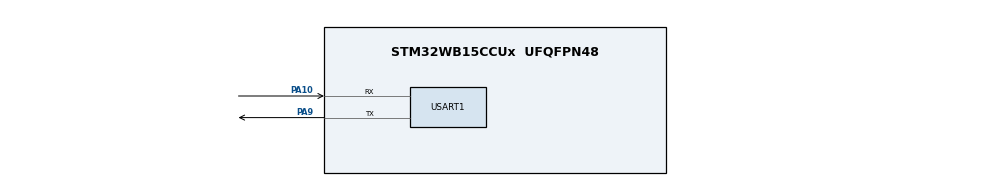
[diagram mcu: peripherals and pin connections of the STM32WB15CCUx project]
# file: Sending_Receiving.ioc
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Mcu.Family=STM32WB
Mcu.Name=STM32WB15CCUx
Mcu.Package=UFQFPN48
NUCLEO-WB15CC.BUTTON=1
NUCLEO-WB15CC.BUTTON2=1
NUCLEO-WB15CC.BUTTON3=1
NUCLEO-WB15CC.LD1=true
NUCLEO-WB15CC.LD2=true
NUCLEO-WB15CC.LD3=true
NUCLEO-WB15CC.VCP=false
NVIC.EXTI0_IRQn=true\:0\:0\:false\:false\:true\:true\:true\:true
NVIC.EXTI4_IRQn=true\:0\:0\:false\:false\:true\:true\:true\:true
NVIC.EXTI9_5_IRQn=true\:0\:0\:false\:false\:true\:true\:true\:true
NVIC.HSEM_IRQn=true\:0\:0\:false\:false\:true\:false\:true\:true
NVIC.IPCC_C1_RX_IRQn=true\:0\:0\:false\:false\:true\:true\:true\:true
NVIC.IPCC_C1_TX_IRQn=true\:0\:0\:false\:false\:true\:true\:true\:true
NVIC.PriorityGroup=NVIC_PRIORITYGROUP_4
NVIC.RTC_WKUP_IRQn=true\:0\:0\:false\:false\:true\:true\:true\:true
NVIC.TIM1_BRK_IRQn=true\:0\:0\:false\:false\:true\:true\:true\:true
NVIC.TIM1_CC_IRQn=true\:0\:0\:false\:false\:true\:true\:true\:true
NVIC.TIM1_TRG_COM_IRQn=true\:0\:0\:false\:false\:true\:true\:true\:true
NVIC.TIM1_UP_IRQn=true\:0\:0\:false\:false\:true\:true\:true\:true
OSC_IN.GPIO_Label=RCC_OSC_IN
OSC_IN.Mode=HSE-External-Oscillator
OSC_IN.Signal=RCC_OSC_IN
OSC_OUT.GPIO_Label=RCC_OSC_OUT
OSC_OUT.Mode=HSE-External-Oscillator
OSC_OUT.Signal=RCC_OSC_OUT
PA10.Mode=Asynchronous
PA10.Signal=USART1_RX
PA13.GPIO_Label=JTMS
PA13.Signal=SYS_JTMS-SWDIO
PA14.GPIO_Label=JTCK
PA14.Signal=SYS_JTCK-SWCLK
PA9.Mode=Asynchronous
PA9.Signal=USART1_TX
PB3.GPIO_Label=JTDO
PB3.Signal=SYS_JTDO-SWO
PC14-OSC32_IN.GPIO_Label=RCC_OSC32_IN
PC14-OSC32_IN.Mode=LSE-External-Oscillator
PC14-OSC32_IN.Signal=RCC_OSC32_IN
PC15-OSC32_OUT.GPIO_Label=RCC_OSC32_OUT
PC15-OSC32_OUT.Mode=LSE-External-Oscillator
PC15-OSC32_OUT.Signal=RCC_OSC32_OUT
ProjectManager.HeapSize=0x200
ProjectManager.StackSize=0x400
ProjectManager.TargetToolchain=STM32CubeIDE
RCC.AHBFreq_Value=32000000
RCC.APB1Freq_Value=32000000
RCC.APB1TimFreq_Value=32000000
RCC.APB2Freq_Value=32000000
RCC.APB2TimFreq_Value=32000000
RCC.APB3Freq_Value=16000000
RCC.CortexFreq_Value=32000000
RCC.HCLKFreq_Value=32000000
RCC.HSE_VALUE=32000000
RCC.HSI_VALUE=16000000
RCC.LSE_Drive_Capability=RCC_LSEDRIVE_LOW
RCC.MSIClockRange=RCC_MSIRANGE_10
RCC.RFWKPClockSelection=RCC_RFWKPCLKSOURCE_LSE
RCC.RTCClockSelection=RCC_RTCCLKSOURCE_LSE
RCC.SYSCLKFreq_VALUE=32000000
RCC.VCOOutputFreq_Value=256000000
RF1.Mode=RF1_Activate
RF1.Signal=RF_RF1
STM32_WPAN.AD_TYPE_COMPLETE_LOCAL_NAME=STM32-NUCLEO
STM32_WPAN.AD_TYPE_COMPLETE_LOCAL_NAME_LENGTH=13
STM32_WPAN.CFG_LSCLK_LSE=0
STM32_WPAN.CUSTOM_P2P_SERVER=Disabled
STM32_WPAN.CUSTOM_TEMPLATE=Enabled
STM32_WPAN.INCLUDE_AD_TYPE_COMPLETE_LOCAL_NAME=1
STM32_WPAN.NUMBER_OF_SERVICES=1
STM32_WPAN.SERVICE1_CHAR1_GATT_NOTIFY_ATTRIBUTE_WRITE=GATT_NOTIFY_ATTRIBUTE_WRITE
STM32_WPAN.SERVICE1_CHAR1_GATT_NOTIFY_READ_REQ_AND_WAIT_FOR_APPL_RESP=\ 
STM32_WPAN.SERVICE1_CHAR1_GATT_NOTIFY_WRITE_REQ_AND_WAIT_FOR_APPL_RESP=\ 
STM32_WPAN.SERVICE1_CHAR1_LONG_NAME=myCharWrite
STM32_WPAN.SERVICE1_CHAR1_PROP_WRITE=CHAR_PROP_WRITE
STM32_WPAN.SERVICE1_CHAR1_SHORT_NAME=myCharWrite
STM32_WPAN.SERVICE1_CHAR1_VALUE_LENGTH=7
STM32_WPAN.SERVICE1_CHAR2_GATT_NOTIFY_ATTRIBUTE_WRITE=GATT_NOTIFY_ATTRIBUTE_WRITE
STM32_WPAN.SERVICE1_CHAR2_GATT_NOTIFY_NOTIFICATION_COMPLETION=GATT_NOTIFY_NOTIFICATION_COMPLETION
STM32_WPAN.SERVICE1_CHAR2_GATT_NOTIFY_READ_REQ_AND_WAIT_FOR_APPL_RESP=GATT_NOTIFY_READ_REQ_AND_WAIT_FOR_APPL_RESP
STM32_WPAN.SERVICE1_CHAR2_GATT_NOTIFY_WRITE_REQ_AND_WAIT_FOR_APPL_RESP=GATT_NOTIFY_WRITE_REQ_AND_WAIT_FOR_APPL_RESP
STM32_WPAN.SERVICE1_CHAR2_LONG_NAME=myCharNotify
STM32_WPAN.SERVICE1_CHAR2_PROP_NOTIFY=CHAR_PROP_NOTIFY
STM32_WPAN.SERVICE1_CHAR2_SHORT_NAME=myCharNotify
STM32_WPAN.SERVICE1_CHAR2_UUID=10 00
STM32_WPAN.SERVICE1_CHAR2_VALUE_LENGTH=7
STM32_WPAN.SERVICE1_LONG_NAME=mySvc
STM32_WPAN.SERVICE1_NUMBER_OF_CHARACTERISTICS=2
STM32_WPAN.SERVICE1_SHORT_NAME=mySvc
STM32_WPAN.SERVICE1_UUID_128_INPUT_TYPE=0
TIM1.Period=49999
TIM1.Prescaler=63
USART1.VirtualMode-Asynchronous=VM_ASYNC
VP_HSEM_VS_HSEM.Mode=HSEM_Activate
VP_IPCC_VS_IPCC.Mode=IPCC_Activate
VP_MEMORYMAP_VS_MEMORYMAP.Mode=CurAppReg
VP_NUCLEO-WB15CC_VS_BSP_COMMON.Mode=COMMON
VP_RTC_VS_RTC_Activate.Mode=RTC_Enabled
VP_RTC_VS_RTC_WakeUp_intern.Mode=WakeUp
VP_SEQUENCER_VS_SEQUENCER.Mode=SEQUENCER_Enabled
VP_STM32_WPAN_VS_BLE_HOST.Mode=STM32_WPAN_Enabled
VP_TIM1_VS_ClockSourceINT.Mode=Internal
VP_TINY_LPM_VS_TINY_LPM.Mode=TINY_LPM_Enabled
board=NUCLEO-WB15CC

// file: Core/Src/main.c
/* USER CODE BEGIN Header */
/**
  ******************************************************************************
  * @file           : main.c
  * @brief          : Main program body
  ******************************************************************************
  * @attention
  *
  * Copyright (c) 2025 STMicroelectronics.
  * All rights reserved.
  *
  * This software is licensed under terms that can be found in the LICENSE file
  * in the root directory of this software component.
  * If no LICENSE file comes with this software, it is provided AS-IS.
  *
  ******************************************************************************
  */
/* USER CODE END Header */
#include "main.h"

/* USER CODE BEGIN PD */
#include "custom_app.h"
/* USER CODE END PD */

IPCC_HandleTypeDef hipcc;

RTC_HandleTypeDef hrtc;

TIM_HandleTypeDef htim1;

UART_HandleTypeDef huart1;

/* USER CODE BEGIN PV */
led_struct_t LED[] = {
    {LED1_GPIO_PORT, LED1_PIN},
    {LED2_GPIO_PORT, LED2_PIN},
    {LED3_GPIO_PORT, LED3_PIN}
};
/* USER CODE END PV */

void SystemClock_Config(void);
void PeriphCommonClock_Config(void);
static void MX_RF_Init(void);
static void MX_GPIO_Init(void);
static void MX_IPCC_Init(void);
static void MX_RTC_Init(void);
static void MX_USART1_UART_Init(void);
static void MX_TIM1_Init(void);

/* USER CODE BEGIN 0 */
int __io_putchar(int ch) //function used to print() in usart
{
  if (ch == '\n') {
    __io_putchar('\r');
  }

  HAL_UART_Transmit(&huart1, (uint8_t*)&ch, 1, HAL_MAX_DELAY);

  return 1;
}
/* USER CODE END 0 */

int main(void)
{

  /* MCU Configuration--------------------------------------------------------*/

  /* Reset of all peripherals, Initializes the Flash interface and the Systick. */
  HAL_Init();
  /* Config code for STM32_WPAN (HSE Tuning must be done before system clock configuration) */
  MX_APPE_Config();

  /* Configure the system clock */
  SystemClock_Config();

  /* Configure the peripherals common clocks */
  PeriphCommonClock_Config();

  /* IPCC initialisation */
  MX_IPCC_Init();

  /* Initialize all configured peripherals */
  MX_RF_Init();
  MX_GPIO_Init();
  MX_RTC_Init();
  MX_USART1_UART_Init();
  MX_TIM1_Init();

  /* Init code for STM32_WPAN */
  MX_APPE_Init();

  /* Initialize leds */
  BSP_LED_Init(LED_BLUE);
  BSP_LED_Init(LED_GREEN);
  BSP_LED_Init(LED_RED);

  /* Initialize USER push-button, will be used to trigger an interrupt each time it's pressed.*/
  BSP_PB_Init(BUTTON_SW1, BUTTON_MODE_EXTI);
  BSP_PB_Init(BUTTON_SW2, BUTTON_MODE_EXTI);
  BSP_PB_Init(BUTTON_SW3, BUTTON_MODE_EXTI);

  /* Infinite loop */
  /* USER CODE BEGIN WHILE */
  uint32_t last_time = 0;  // Przechowuje czas ostatniego wysłania danych
  printf("Starting");
//  HAL_TIM_Base_Start_IT(&htim1);
  while (1)
  {

    /* USER CODE END WHILE */
    MX_APPE_Process();

  }
}

void SystemClock_Config(void)
{
  RCC_OscInitTypeDef RCC_OscInitStruct = {0};
  RCC_ClkInitTypeDef RCC_ClkInitStruct = {0};

  /** Configure LSE Drive Capability
  */
  HAL_PWR_EnableBkUpAccess();
  __HAL_RCC_LSEDRIVE_CONFIG(RCC_LSEDRIVE_LOW);

  /** Initializes the RCC Oscillators according to the specified parameters
  * in the RCC_OscInitTypeDef structure.
  */
  RCC_OscInitStruct.OscillatorType = RCC_OSCILLATORTYPE_HSI|RCC_OSCILLATORTYPE_HSE
                              |RCC_OSCILLATORTYPE_LSE|RCC_OSCILLATORTYPE_MSI;
  RCC_OscInitStruct.HSEState = RCC_HSE_ON;
  RCC_OscInitStruct.LSEState = RCC_LSE_ON;
  RCC_OscInitStruct.HSIState = RCC_HSI_ON;
  RCC_OscInitStruct.MSIState = RCC_MSI_ON;
  RCC_OscInitStruct.HSICalibrationValue = RCC_HSICALIBRATION_DEFAULT;
  RCC_OscInitStruct.MSICalibrationValue = RCC_MSICALIBRATION_DEFAULT;
  RCC_OscInitStruct.MSIClockRange = RCC_MSIRANGE_10;
  RCC_OscInitStruct.PLL.PLLState = RCC_PLL_NONE;
  if (HAL_RCC_OscConfig(&RCC_OscInitStruct) != HAL_OK)
  {
    Error_Handler();
  }

  /** Configure the SYSCLKSource, HCLK, PCLK1 and PCLK2 clocks dividers
  */
  RCC_ClkInitStruct.ClockType = RCC_CLOCKTYPE_HCLK4|RCC_CLOCKTYPE_HCLK2
                              |RCC_CLOCKTYPE_HCLK|RCC_CLOCKTYPE_SYSCLK
                              |RCC_CLOCKTYPE_PCLK1|RCC_CLOCKTYPE_PCLK2;
  RCC_ClkInitStruct.SYSCLKSource = RCC_SYSCLKSOURCE_MSI;
  RCC_ClkInitStruct.AHBCLKDivider = RCC_SYSCLK_DIV1;
  RCC_ClkInitStruct.APB1CLKDivider = RCC_HCLK_DIV1;
  RCC_ClkInitStruct.APB2CLKDivider = RCC_HCLK_DIV1;
  RCC_ClkInitStruct.AHBCLK2Divider = RCC_SYSCLK_DIV1;
  RCC_ClkInitStruct.AHBCLK4Divider = RCC_SYSCLK_DIV1;

  if (HAL_RCC_ClockConfig(&RCC_ClkInitStruct, FLASH_LATENCY_1) != HAL_OK)
  {
    Error_Handler();
  }

  /** Enable MSI Auto calibration
  */
  HAL_RCCEx_EnableMSIPLLMode();
}

void PeriphCommonClock_Config(void)
{
  RCC_PeriphCLKInitTypeDef PeriphClkInitStruct = {0};

  /** Initializes the peripherals clock
  */
  PeriphClkInitStruct.PeriphClockSelection = RCC_PERIPHCLK_SMPS|RCC_PERIPHCLK_RFWAKEUP;
  PeriphClkInitStruct.RFWakeUpClockSelection = RCC_RFWKPCLKSOURCE_LSE;
  PeriphClkInitStruct.SmpsClockSelection = RCC_SMPSCLKSOURCE_HSI;
  PeriphClkInitStruct.SmpsDivSelection = RCC_SMPSCLKDIV_RANGE1;

  if (HAL_RCCEx_PeriphCLKConfig(&PeriphClkInitStruct) != HAL_OK)
  {
    Error_Handler();
  }
}

static void MX_IPCC_Init(void)
{

  hipcc.Instance = IPCC;
  if (HAL_IPCC_Init(&hipcc) != HAL_OK)
  {
    Error_Handler();
  }

}

static void MX_RF_Init(void)
{

}

static void MX_RTC_Init(void)
{

  /** Initialize RTC Only
  */
  hrtc.Instance = RTC;
  hrtc.Init.HourFormat = RTC_HOURFORMAT_24;
  hrtc.Init.AsynchPrediv = CFG_RTC_ASYNCH_PRESCALER;
  hrtc.Init.SynchPrediv = CFG_RTC_SYNCH_PRESCALER;
  hrtc.Init.OutPut = RTC_OUTPUT_DISABLE;
  hrtc.Init.OutPutPolarity = RTC_OUTPUT_POLARITY_HIGH;
  hrtc.Init.OutPutRemap = RTC_OUTPUT_REMAP_NONE;
  if (HAL_RTC_Init(&hrtc) != HAL_OK)
  {
    Error_Handler();
  }

  /** Enable the WakeUp
  */
  if (HAL_RTCEx_SetWakeUpTimer_IT(&hrtc, 0, RTC_WAKEUPCLOCK_RTCCLK_DIV16) != HAL_OK)
  {
    Error_Handler();
  }

}

static void MX_TIM1_Init(void)
{

  TIM_ClockConfigTypeDef sClockSourceConfig = {0};
  TIM_MasterConfigTypeDef sMasterConfig = {0};

  htim1.Instance = TIM1;
  htim1.Init.Prescaler = 63;
  htim1.Init.CounterMode = TIM_COUNTERMODE_UP;
  htim1.Init.Period = 49999;
  htim1.Init.ClockDivision = TIM_CLOCKDIVISION_DIV1;
  htim1.Init.RepetitionCounter = 0;
  htim1.Init.AutoReloadPreload = TIM_AUTORELOAD_PRELOAD_DISABLE;
  if (HAL_TIM_Base_Init(&htim1) != HAL_OK)
  {
    Error_Handler();
  }
  sClockSourceConfig.ClockSource = TIM_CLOCKSOURCE_INTERNAL;
  if (HAL_TIM_ConfigClockSource(&htim1, &sClockSourceConfig) != HAL_OK)
  {
    Error_Handler();
  }
  sMasterConfig.MasterOutputTrigger = TIM_TRGO_RESET;
  sMasterConfig.MasterOutputTrigger2 = TIM_TRGO2_RESET;
  sMasterConfig.MasterSlaveMode = TIM_MASTERSLAVEMODE_DISABLE;
  if (HAL_TIMEx_MasterConfigSynchronization(&htim1, &sMasterConfig) != HAL_OK)
  {
    Error_Handler();
  }

}

static void MX_USART1_UART_Init(void)
{

  huart1.Instance = USART1;
  huart1.Init.BaudRate = 115200;
  huart1.Init.WordLength = UART_WORDLENGTH_8B;
  huart1.Init.StopBits = UART_STOPBITS_1;
  huart1.Init.Parity = UART_PARITY_NONE;
  huart1.Init.Mode = UART_MODE_TX_RX;
  huart1.Init.HwFlowCtl = UART_HWCONTROL_NONE;
  huart1.Init.OverSampling = UART_OVERSAMPLING_16;
  huart1.Init.OneBitSampling = UART_ONE_BIT_SAMPLE_DISABLE;
  huart1.Init.ClockPrescaler = UART_PRESCALER_DIV1;
  huart1.AdvancedInit.AdvFeatureInit = UART_ADVFEATURE_NO_INIT;
  if (HAL_UART_Init(&huart1) != HAL_OK)
  {
    Error_Handler();
  }
  if (HAL_UARTEx_SetTxFifoThreshold(&huart1, UART_TXFIFO_THRESHOLD_1_8) != HAL_OK)
  {
    Error_Handler();
  }
  if (HAL_UARTEx_SetRxFifoThreshold(&huart1, UART_RXFIFO_THRESHOLD_1_8) != HAL_OK)
  {
    Error_Handler();
  }
  if (HAL_UARTEx_DisableFifoMode(&huart1) != HAL_OK)
  {
    Error_Handler();
  }

}

static void MX_GPIO_Init(void)
{

  /* GPIO Ports Clock Enable */
  __HAL_RCC_GPIOC_CLK_ENABLE();
  __HAL_RCC_GPIOA_CLK_ENABLE();
  __HAL_RCC_GPIOB_CLK_ENABLE();

}

/* USER CODE BEGIN 4 */
//void HAL_TIM_PeriodElapsedCallback(TIM_HandleTypeDef *htim)
//{
//    if (htim->Instance == TIM1) // Gdzie TIMx to timer skonfigurowany na 100 ms
//    {
//    	UTIL_SEQ_SetTask(1 << CFG_TASK_TIMER_SECOND_ID, CFG_SCH_PRIO_0);
//    }
//}
void BSP_PB_Callback(Button_TypeDef Button)
{
    if (Button == BUTTON_SW1)
    {
        // Obsługuje przycisk SW1
    	if(payload.button_1_state != 1)
        	payload.button_1_state = 1;  // Ustawienie stanu przycisku SW1
    	else
    		payload.button_1_state = 0;  // Ustawienie stanu przycisku SW1
        //Custom_Mycharnotify_Update_Char();  // Wyślij dane
    }
    else if (Button == BUTTON_SW2)
    {
        // Obsługuje przycisk SW2
    	if(payload.button_2_state != 1)
        	payload.button_2_state = 1;  // Ustawienie stanu przycisku SW2
    	else
    		payload.button_2_state = 0;  // Ustawienie stanu przycisku SW1
        //Custom_Mycharnotify_Update_Char();  // Wyślij dane
    }
    else if (Button == BUTTON_SW3)
    {
        // Obsługuje przycisk SW3
    	if(payload.button_3_state != 1)
        	payload.button_3_state = 1; // Ustawienie stanu przycisku SW2
    	else
    		payload.button_3_state = 0;  // Ustawienie stanu przycisku SW1
        //Custom_Mycharnotify_Update_Char();  // Wyślij dane
    }
}
/* USER CODE END 4 */

void Error_Handler(void)
{
  __disable_irq();
  while (1)
  {
  }
}
